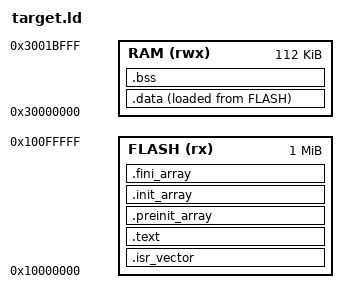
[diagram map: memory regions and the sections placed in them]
/* MCXW716C secure aliases: flash 0x10000000, STCM 0x30000000. The FMU
 * routines go to SRAM with .data: the flash is not readable mid-command. */
MEMORY
{
    FLASH (rx)  : ORIGIN = 0x10000000, LENGTH = 0x00100000
    RAM   (rwx) : ORIGIN = 0x30000000, LENGTH = 0x0001C000
}

_estack = ORIGIN(RAM) + LENGTH(RAM);
_sidata = LOADADDR(.data);

SECTIONS
{
    .isr_vector :
    {
        KEEP(*(.isr_vector))
    } > FLASH

    .text :
    {
        *(.text*)
        *(.rodata*)
        *(.ARM.extab* .gnu.linkonce.armextab.*)
        *(.ARM.exidx* .gnu.linkonce.armexidx.*)
        *(.glue_7)
        *(.glue_7t)
        *(.eh_frame)
    } > FLASH

    .preinit_array :
    {
        __preinit_array_start = .;
        KEEP(*(.preinit_array*))
        __preinit_array_end = .;
    } > FLASH

    .init_array :
    {
        __init_array_start = .;
        KEEP(*(.init_array*))
        __init_array_end = .;
    } > FLASH

    .fini_array :
    {
        __fini_array_start = .;
        KEEP(*(.fini_array*))
        __fini_array_end = .;
    } > FLASH

    .data :
    {
        . = ALIGN(4);
        _sdata = .;
        KEEP(*(.ramfunc*))
        . = ALIGN(4);
        *(.data*)
        . = ALIGN(4);
        _edata = .;
    } > RAM AT > FLASH

    .bss (NOLOAD) :
    {
        . = ALIGN(4);
        _sbss = .;
        *(.bss*)
        *(COMMON)
        . = ALIGN(4);
        _ebss = .;
    } > RAM
}
